# CY8C5868AXI_LP035 register map
File version: 0.1
Registers are 8-bit, read-write, no defined reset value unless marked. A register's access mark holds for its fields unless they carry their own. Offsets are from the block's base; [hi:lo] are bit positions; {n}, {i} and the like mark numbered series; 'fields as' and 'values as' point back to an identical list.

## CapSense
Base 0x00000000
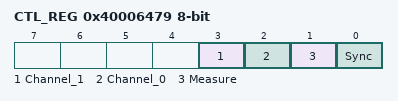
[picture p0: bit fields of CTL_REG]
0x40006479 CTL_REG — CapSense Control Register
  [3] Channel_1 ro — Channel 1 Enable
    0=Disabled (Channel 1 scanning is disabled); 1=Enabled (Channel 1 scanning is enabled)
  [2] Channel_0 ro — Channel 0 Enable
    0=Disabled (Channel 0 scanning is disabled); 1=Enabled (Channel 0 scanning is enabled)
  [1] Measure ro — Measurement Enable
    0=Disabled (Capacitance measurement is disabled); 1=Enabled (Capacitance measurement is enabled)
  [0] Sync ro — Reset Digital and Pre-Charge Clocks
    0=Disabled (Clocks are in the reset state); 1=Enabled (Clocks are enabled)
0x4000659A ScanSpeed_CTL_REG — CapSense Clock Prescaler Control Register
  [3] Counter ro — Clock Prescaler Enable
    0=Disabled (Prescaler counter is disabled); 1=Enabled (Prescaler counter is enabled)

## CapSense_IdacCH0
Base 0x00000000
0x400043A8 IDAC8_PM_ACT_CFG — Active Power Mode Configuration Register 8
  [3:0] en_dac — Enable DAC block(s). Populated subsystems are counted from the LSB.
0x400043B8 IDAC8_PM_STBY_CFG — Standby Power Mode Configuration Register 8
  fields as IDAC8_PM_ACT_CFG
0x40004608 IDAC8_TR
  [7:0] tr — 8 Calibration bits
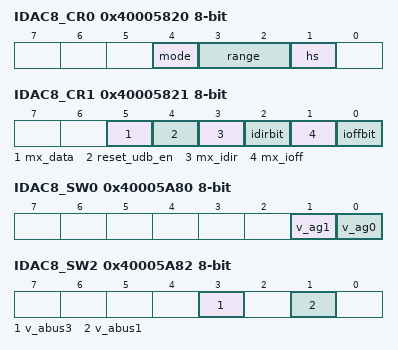
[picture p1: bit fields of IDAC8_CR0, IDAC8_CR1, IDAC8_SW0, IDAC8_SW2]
0x40005820 IDAC8_CR0 — DAC Block Control Register 0
  [4] mode ro — Mode Bit
    0=DAC_MODE_V (voltage DAC); 1=DAC_MODE_I (current DAC)
  [3:2] range — Ranges for mode=0 (VDAC) and mode=1 (IDAC)
    0=DAC_RANGE_0 (x0=0V to 4*vref (1.024V); 0 to 31.875uA); 1=DAC_RANGE_1 (x1=0V to 16*vref (4.096V); 0 to 255uA); 2=DAC_RANGE_2 (x0=0V to 4*vref (1.024V); 0 to 2.040mA); 3=DAC_RANGE_3 (x1=0V to 16*vref (4.096V); not used)
  [1] hs — High Speed Bit
    0=DAC_HS_LOWPOWER (regular (low power)); 1=DAC_HS_HIGHSPEED (high speed (higher power))
0x40005821 IDAC8_CR1 — DAC Block Control Register 1
  [5] mx_data — Select DATA source
    0=MX_DATA_REG (Select register source); 1=MX_DATA_UDB (Select UDB source)
  [4] reset_udb_en — DAC reset enable
    0=RESET_UDB_EN_DISABLE (Disable DAC Reset Source from UDB); 1=RESET_UDB_EN_ENABLE (Enable DAC Reset Source from UDB)
  [3] mx_idir — Mux selection for DAC current direction control
    0=MX_IDIR_REG (Register source idirbit selected); 1=MX_IDIR_UDB (UDB ictrl selected)
  [2] idirbit — register source for DAC current direction
  [1] mx_ioff — Mux selection for DAC current off control
    0=MX_IOFF_REG (Register source ioffbit selected); 1=MX_IOFF_UDB (UDB ictrl selected)
  [0] ioffbit — register source for DAC current off
0x40005A80 IDAC8_SW0 — DAC Analog Routing Register 0
  [1] v_ag1 — Connect voltage output to analog global of same side
    0=AG_NC (not connected); 1=AG_CONNECTED (Connect to Analog Global)
  [0] v_ag0 — Connect voltage output to analog global of same side
    values as v_ag1
0x40005A82 IDAC8_SW2 — DAC Analog Routing Register 2
  [3] v_abus3 — Connect voltage output to analog (local) bus of the same side
    0=ABUS_NC (not connected); 1=ABUS_CONNECTED (Connect to Analog (local) Bus)
  [1] v_abus1 — Connect voltage output to analog (local) bus of the same side
    values as v_abus3
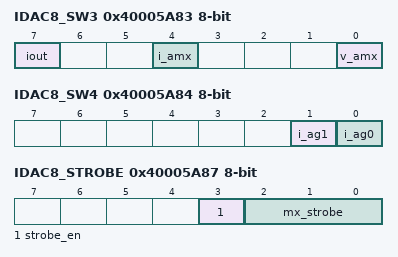
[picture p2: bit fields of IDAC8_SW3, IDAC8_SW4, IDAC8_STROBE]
0x40005A83 IDAC8_SW3 — DAC Analog Routing Register 3
  [7] iout — Connect current output to pad
    0=IOUT_NC (not connected); 1=IOUT_CONNECT (Connect to pad)
  [4] i_amx — Connect current output to Analog Mux Bus
    0=AMX_NC (not connected); 1=AMX_CONNECTED (Connect to AMUXBUS)
  [0] v_amx — Connect voltage output to Analog Mux Bus
    values as i_amx
0x40005A84 IDAC8_SW4 — DAC Analog Routing Register 4
  [1] i_ag1 — Connect current output to analog global of same side
    values as IDAC8_SW0.v_ag1
  [0] i_ag0 — Connect current output to analog global of same side
    values as IDAC8_SW0.v_ag1
0x40005A87 IDAC8_STROBE — DAC Strobe Register
  [3] strobe_en — Strobe gating control
    0=disable strobe; 1=enable strobe
  [2:0] mx_strobe — Strobe source selection
    0=MX_STROBE_BUSWRITE (Select bus write strobe source); 1=MX_STROBE_UDB_SRC (Select UDB strobe source); 2=MX_STROBE_NC_2 (NC); 3=MX_STROBE_NC_3 (NC); {v}=MX_STROBE_CLK_A{v-4}_DIG (Select clk_a{v-4}_dig) (v=4..7)
0x40005B80 IDAC8_D — DAC Data Register
  [7:0] data — 8 DAC Data bits

## Tone_D
Base 0x00000000
0x40006504 Tone_D_COUNTER 16-bit — UDB.A0 - Current Counter Value
0x40006524 Tone_D_PERIOD 16-bit — UDB.D0 - Assigned Period
0x40006534 Tone_D_COMPARE 16-bit — UDB.D1 - Assigned Compare Value
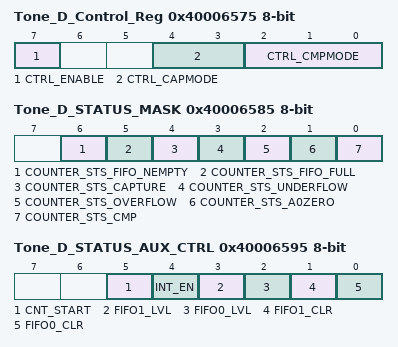
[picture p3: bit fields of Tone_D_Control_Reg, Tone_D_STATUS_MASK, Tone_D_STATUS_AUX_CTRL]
0x40006575 Tone_D_Control_Reg — UDB Control Register - Assigned Control Register Value
  [7] CTRL_ENABLE — Enable Counter
  [4:3] CTRL_CAPMODE — Capture mode
  [2:0] CTRL_CMPMODE — Compare mode
0x40006585 Tone_D_STATUS_MASK — UDB Status bits Interrupt Mask Enable Register
  [6] COUNTER_STS_FIFO_NEMPTY — FIFO Not Empty Status
  [5] COUNTER_STS_FIFO_FULL — FIFO Full Status
  [4] COUNTER_STS_CAPTURE — Capture Status
  [3] COUNTER_STS_UNDERFLOW — Underflow status
  [2] COUNTER_STS_OVERFLOW — Overflow status
  [1] COUNTER_STS_A0ZERO — A0 Zero ouput status
  [0] COUNTER_STS_CMP — Compare output status
0x40006595 Tone_D_STATUS_AUX_CTRL — UDB Auxilliary Control Register
  [5] CNT_START — FIFO0 clear
    0=E_CNT_START0 (Disable counter); 1=E_CNT_START1 (Enable counter)
  [4] INT_EN
    0=E_INT_EN0 (Interrupt disabled); 1=E_INT_EN1 (Interrupt enabled)
  [3] FIFO1_LVL — FIFO level
    0=E_FIFO_LVL_0 (FIFO LVL: input mode: FIFO not full; output mode: FIFO not empty); 1=E_FIFO_LVL_1 (FIFO LVL: input mode: FIFO at least 1/2 empty; output mode: FIFO at least 1/2 full)
  [2] FIFO0_LVL — FIFO level
    values as FIFO1_LVL
  [1] FIFO1_CLR — FIFO1 clear
    0=E_FIFO_CLR_0 (Normal FIFO operation); 1=E_FIFO_CLR_1 (Clear FIFO state)
  [0] FIFO0_CLR — FIFO0 clear
    values as FIFO1_CLR

## HB_ADC — SAR ADC
Base 0x00000000
0x40004616 SAR_TR0 — SAR trim register
{0x40005908+i} SAR_CSR{i} (i=0..6) — SAR status and control register {i}
0x40005B28 SAR_SW0 — SAR Analog Routing Register 0
{0x40005B28+i} SAR_SW{i} (i=2..4) — SAR Analog Routing Register {i}
0x40005B2E SAR_SW6 — SAR Analog Routing Register 6
0x40005B2F SAR_CLK — SAR Clock Selection Register
0x40005BA2 SAR_WRK 16-bit — SAR working register

## Tone_F
Base 0x00000000
0x40006428 Tone_F_COMPARE_Reg 16-bit — UDB.D0 - Assigned Compare Value
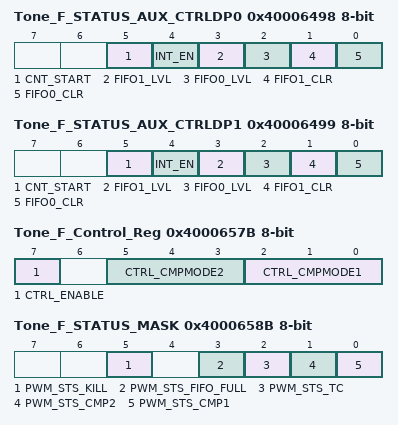
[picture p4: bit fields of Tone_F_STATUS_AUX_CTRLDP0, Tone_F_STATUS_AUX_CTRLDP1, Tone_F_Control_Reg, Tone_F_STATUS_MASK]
0x40006498 Tone_F_STATUS_AUX_CTRLDP0 — UDB Auxilliary Control Register
  [5] CNT_START — FIFO0 clear
    0=E_CNT_START0 (Disable counter); 1=E_CNT_START1 (Enable counter)
  [4] INT_EN
    0=E_INT_EN0 (Interrupt disabled); 1=E_INT_EN1 (Interrupt enabled)
  [3] FIFO1_LVL — FIFO level
    0=E_FIFO_LVL_0 (FIFO LVL: input mode: FIFO not full; output mode: FIFO not empty); 1=E_FIFO_LVL_1 (FIFO LVL: input mode: FIFO at least 1/2 empty; output mode: FIFO at least 1/2 full)
  [2] FIFO0_LVL — FIFO level
    values as FIFO1_LVL
  [1] FIFO1_CLR — FIFO1 clear
    0=E_FIFO_CLR_0 (Normal FIFO operation); 1=E_FIFO_CLR_1 (Clear FIFO state)
  [0] FIFO0_CLR — FIFO0 clear
    values as FIFO1_CLR
0x40006499 Tone_F_STATUS_AUX_CTRLDP1 — UDB Auxilliary Control Register
  fields as Tone_F_STATUS_AUX_CTRLDP0
0x4000657B Tone_F_Control_Reg — UDB Control Register - Assigned Control Register Value
  [7] CTRL_ENABLE — Enable the PWM
  [5:3] CTRL_CMPMODE2 — Compare mode 2
  [2:0] CTRL_CMPMODE1 — Compare mode 1
0x4000658B Tone_F_STATUS_MASK — UDB Status bits Interrupt Mask Enable Register
  [5] PWM_STS_KILL ro — Enables the Interrupt on Kill
  [3] PWM_STS_FIFO_FULL ro — FIFO Full Status Mask
  [2] PWM_STS_TC ro — Enables the Interrupt on Terminal Count
  [1] PWM_STS_CMP2 ro — Enables the Interrupt on Compare 2
  [0] PWM_STS_CMP1 ro — Enables the Interrupt on Compare 1
